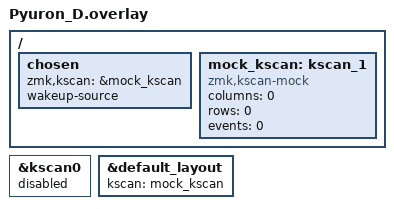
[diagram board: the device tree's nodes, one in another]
#include "Pyuron.dtsi"

/ {
    chosen {
        zmk,kscan = &mock_kscan;
        wakeup-source;
    };

    mock_kscan: kscan_1 {
        compatible = "zmk,kscan-mock";
        columns = <0>;
        rows = <0>;
        events = <0>;
    };
};

&kscan0 {
    status = "disabled";
};

&default_layout {
    kscan = <&mock_kscan>;
};
